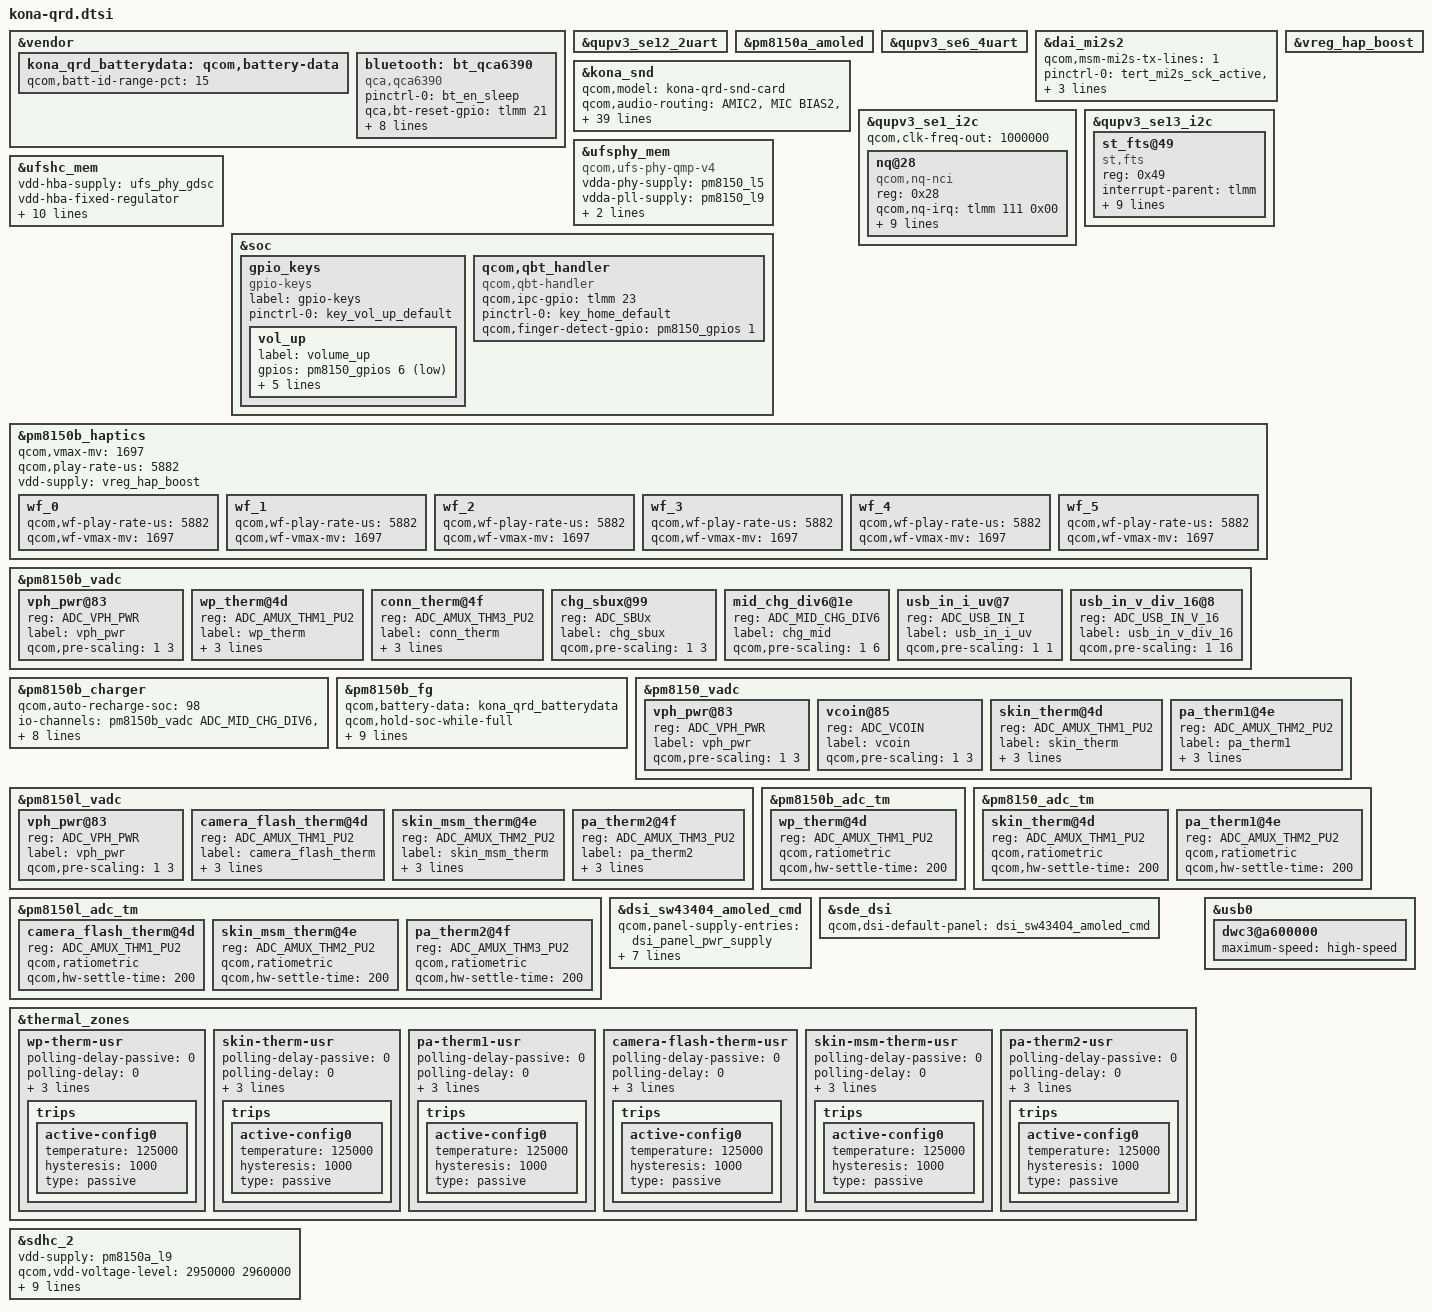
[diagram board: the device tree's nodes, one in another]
// SPDX-License-Identifier: GPL-2.0-only
/*
 * Copyright (c) 2018-2019, The Linux Foundation. All rights reserved.
 */

#include <dt-bindings/gpio/gpio.h>
#include "kona-pmic-overlay.dtsi"
#include "kona-sde-display.dtsi"
#include "kona-camera-sensor-qrd.dtsi"
#include "kona-audio-overlay.dtsi"
#include "kona-thermal-overlay.dtsi"

&vendor {
	kona_qrd_batterydata: qcom,battery-data {
		qcom,batt-id-range-pct = <15>;
		#include "fg-gen4-batterydata-mlp466274-3650mah.dtsi"
	};
};

&qupv3_se12_2uart {
	status = "okay";
};

&pm8150a_amoled {
	status = "ok";
};

&qupv3_se6_4uart {
	status = "ok";
};

&dai_mi2s2 {
	qcom,msm-mi2s-tx-lines = <1>;
	pinctrl-names = "default", "sleep";
	pinctrl-0 = <&tert_mi2s_sck_active &tert_mi2s_ws_active
			&tert_mi2s_sd0_active>;
	pinctrl-1 = <&tert_mi2s_sck_sleep &tert_mi2s_ws_sleep
			&tert_mi2s_sd0_sleep>;
};

&kona_snd {
	qcom,model = "kona-qrd-snd-card";
	qcom,audio-routing =
		"AMIC2", "MIC BIAS2",
		"MIC BIAS2", "Analog Mic2",
		"TX DMIC0", "MIC BIAS3",
		"MIC BIAS3", "Digital Mic0",
		"TX DMIC1", "MIC BIAS3",
		"MIC BIAS3", "Digital Mic1",
		"TX DMIC2", "MIC BIAS1",
		"MIC BIAS1", "Digital Mic2",
		"TX DMIC3", "MIC BIAS1",
		"MIC BIAS1", "Digital Mic3",
		"TX DMIC5", "MIC BIAS4",
		"MIC BIAS4", "Digital Mic5",
		"IN1_HPHL", "HPHL_OUT",
		"IN2_HPHR", "HPHR_OUT",
		"IN3_AUX", "AUX_OUT",
		"TX SWR_ADC0", "ADC1_OUTPUT",
		"TX SWR_ADC1", "ADC2_OUTPUT",
		"TX SWR_ADC2", "ADC3_OUTPUT",
		"TX SWR_ADC3", "ADC4_OUTPUT",
		"TX SWR_DMIC0", "DMIC1_OUTPUT",
		"TX SWR_DMIC1", "DMIC2_OUTPUT",
		"TX SWR_DMIC2", "DMIC3_OUTPUT",
		"TX SWR_DMIC3", "DMIC4_OUTPUT",
		"TX SWR_DMIC4", "DMIC5_OUTPUT",
		"TX SWR_DMIC5", "DMIC6_OUTPUT",
		"TX SWR_DMIC6", "DMIC7_OUTPUT",
		"TX SWR_DMIC7", "DMIC8_OUTPUT",
		"WSA SRC0_INP", "SRC0",
		"WSA_TX DEC0_INP", "TX DEC0 MUX",
		"WSA_TX DEC1_INP", "TX DEC1 MUX",
		"RX_TX DEC0_INP", "TX DEC0 MUX",
		"RX_TX DEC1_INP", "TX DEC1 MUX",
		"RX_TX DEC2_INP", "TX DEC2 MUX",
		"RX_TX DEC3_INP", "TX DEC3 MUX",
		"SpkrRight IN", "WSA_SPK2 OUT",
		"VA_AIF1 CAP", "VA_SWR_CLK",
		"VA_AIF2 CAP", "VA_SWR_CLK",
		"VA_AIF3 CAP", "VA_SWR_CLK",
		"VA DMIC0", "MIC BIAS3",
		"VA DMIC1", "MIC BIAS3",
		"VA DMIC2", "MIC BIAS1",
		"VA DMIC3", "MIC BIAS1",
		"VA DMIC5", "MIC BIAS4",
		"VA SWR_MIC0", "DMIC1_OUTPUT",
		"VA SWR_MIC1", "DMIC2_OUTPUT",
		"VA SWR_MIC2", "DMIC3_OUTPUT",
		"VA SWR_MIC3", "DMIC4_OUTPUT",
		"VA SWR_MIC4", "DMIC5_OUTPUT",
		"VA SWR_MIC5", "DMIC6_OUTPUT",
		"VA SWR_MIC6", "DMIC7_OUTPUT",
		"VA SWR_MIC7", "DMIC8_OUTPUT",
		"VA SWR_ADC1", "ADC2_OUTPUT";
	qcom,wsa-max-devs = <1>;
	qcom,wsa-devs = <&wsa881x_0212>, <&wsa881x_0214>;
	qcom,wsa-aux-dev-prefix = "SpkrRight", "SpkrRight";

	qcom,msm-mbhc-usbc-audio-supported = <1>;
	qcom,msm-mbhc-hphl-swh = <0>;
	qcom,msm-mbhc-gnd-swh = <0>;
};

&qupv3_se1_i2c {
	status = "ok";
	qcom,clk-freq-out = <1000000>;
	#address-cells = <1>;
	#size-cells = <0>;
	nq@28 {
		compatible = "qcom,nq-nci";
		reg = <0x28>;
		qcom,nq-irq = <&tlmm 111 0x00>;
		qcom,nq-ven = <&tlmm 6 0x00>;
		qcom,nq-firm = <&tlmm 110 0x00>;
		qcom,nq-clkreq = <&tlmm 7 0x00>;
		interrupt-parent = <&tlmm>;
		interrupts = <111 0>;
		interrupt-names = "nfc_irq";
		pinctrl-names = "nfc_active", "nfc_suspend";
		pinctrl-0 = <&nfc_int_active &nfc_enable_active
				&nfc_clk_req_active>;
		pinctrl-1 = <&nfc_int_suspend &nfc_enable_suspend
				&nfc_clk_req_suspend>;
	};
};

&qupv3_se13_i2c {
	#address-cells = <1>;
	#size-cells = <0>;

	status = "ok";

	st_fts@49 {
		compatible = "st,fts";
		reg = <0x49>;
		interrupt-parent = <&tlmm>;
		interrupts = <39 0x2008>;
		vdd-supply = <&pm8150a_l1>;
		avdd-supply = <&pm8150_l13>;
		pinctrl-names = "pmx_ts_active", "pmx_ts_suspend";
		pinctrl-0 = <&ts_active>;
		pinctrl-1 = <&ts_int_suspend &ts_reset_suspend>;
		st,irq-gpio = <&tlmm 39 0x2008>;
		st,reset-gpio = <&tlmm 38 0x00>;
		st,regulator_dvdd = "vdd";
		st,regulator_avdd = "avdd";
	};
};

&ufsphy_mem {
	compatible = "qcom,ufs-phy-qmp-v4";

	vdda-phy-supply = <&pm8150_l5>;
	vdda-pll-supply = <&pm8150_l9>;
	vdda-phy-max-microamp = <89900>;
	vdda-pll-max-microamp = <18800>;

	status = "ok";
};

&ufshc_mem {
	vdd-hba-supply = <&ufs_phy_gdsc>;
	vdd-hba-fixed-regulator;
	vcc-supply = <&pm8150_l17>;
	vcc-voltage-level = <2504000 2950000>;
	vcc-low-voltage-sup;
	vccq-supply = <&pm8150_l6>;
	vccq2-supply = <&pm8150_s4>;
	vcc-max-microamp = <800000>;
	vccq-max-microamp = <800000>;
	vccq2-max-microamp = <800000>;

	qcom,vddp-ref-clk-supply = <&pm8150_l6>;
	qcom,vddp-ref-clk-max-microamp = <100>;

	status = "ok";
};

&soc {
	gpio_keys {
		compatible = "gpio-keys";
		label = "gpio-keys";

		pinctrl-names = "default";
		pinctrl-0 = <&key_vol_up_default>;

		vol_up {
			label = "volume_up";
			gpios = <&pm8150_gpios 6 GPIO_ACTIVE_LOW>;
			linux,input-type = <1>;
			linux,code = <KEY_VOLUMEUP>;
			gpio-key,wakeup;
			debounce-interval = <15>;
			linux,can-disable;
		};
	};

	qcom,qbt_handler {
		compatible = "qcom,qbt-handler";
		qcom,ipc-gpio = <&tlmm 23 0>;
		pinctrl-names = "default";
		pinctrl-0 = <&key_home_default>;
		qcom,finger-detect-gpio = <&pm8150_gpios 1 0>;
	};
};

&vreg_hap_boost {
	status = "ok";
};

&pm8150b_haptics {
	qcom,vmax-mv = <1697>;
	qcom,play-rate-us = <5882>;
	vdd-supply = <&vreg_hap_boost>;

	wf_0 {
		/* CLICK */
		qcom,wf-play-rate-us = <5882>;
		qcom,wf-vmax-mv = <1697>;
	};

	wf_1 {
		/* DOUBLE CLICK */
		qcom,wf-play-rate-us = <5882>;
		qcom,wf-vmax-mv = <1697>;
	};

	wf_2 {
		/* TICK */
		qcom,wf-play-rate-us = <5882>;
		qcom,wf-vmax-mv = <1697>;
	};

	wf_3 {
		/* THUD */
		qcom,wf-play-rate-us = <5882>;
		qcom,wf-vmax-mv = <1697>;
	};

	wf_4 {
		/* POP */
		qcom,wf-play-rate-us = <5882>;
		qcom,wf-vmax-mv = <1697>;
	};

	wf_5 {
		/* HEAVY CLICK */
		qcom,wf-play-rate-us = <5882>;
		qcom,wf-vmax-mv = <1697>;
	};
};

&pm8150b_vadc {
	#address-cells = <1>;
	#size-cells = <0>;

	vph_pwr@83 {
		reg = <ADC_VPH_PWR>;
		label = "vph_pwr";
		qcom,pre-scaling = <1 3>;
	};

	wp_therm@4d {
		reg = <ADC_AMUX_THM1_PU2>;
		label = "wp_therm";
		qcom,ratiometric;
		qcom,hw-settle-time = <200>;
		qcom,pre-scaling = <1 1>;
	};

	conn_therm@4f {
		reg = <ADC_AMUX_THM3_PU2>;
		label = "conn_therm";
		qcom,ratiometric;
		qcom,hw-settle-time = <200>;
		qcom,pre-scaling = <1 1>;
	};

	chg_sbux@99 {
		reg = <ADC_SBUx>;
		label = "chg_sbux";
		qcom,pre-scaling = <1 3>;
	};

	mid_chg_div6@1e {
		reg = <ADC_MID_CHG_DIV6>;
		label = "chg_mid";
		qcom,pre-scaling = <1 6>;
	};

	usb_in_i_uv@7 {
		reg = <ADC_USB_IN_I>;
		label = "usb_in_i_uv";
		qcom,pre-scaling = <1 1>;
	};

	usb_in_v_div_16@8 {
		reg = <ADC_USB_IN_V_16>;
		label = "usb_in_v_div_16";
		qcom,pre-scaling = <1 16>;
	};
};

&pm8150b_charger {
	status = "ok";
	qcom,auto-recharge-soc = <98>;
	io-channels = <&pm8150b_vadc ADC_MID_CHG_DIV6>,
		      <&pm8150b_vadc ADC_USB_IN_I>,
		      <&pm8150b_vadc ADC_SBUx>,
		      <&pm8150b_vadc ADC_VPH_PWR>,
		      <&pm8150b_vadc ADC_CHG_TEMP>;
	io-channel-names = "mid_voltage",
			   "usb_in_current",
			   "sbux_res",
			   "vph_voltage",
			   "chg_temp";
	qcom,battery-data = <&kona_qrd_batterydata>;
	qcom,sw-jeita-enable;
	qcom,wd-bark-time-secs = <16>;
	qcom,suspend-input-on-debug-batt;
};

&pm8150b_fg {
	status = "ok";
	qcom,battery-data = <&kona_qrd_batterydata>;
	qcom,hold-soc-while-full;
	qcom,linearize-soc;
	qcom,five-pin-battery;
	qcom,cl-wt-enable;
	/* ESR fast calibration */
	qcom,fg-esr-timer-chg-fast = <0 7>;
	qcom,fg-esr-timer-dischg-fast = <0 7>;
	qcom,fg-esr-timer-chg-slow = <0 96>;
	qcom,fg-esr-timer-dischg-slow = <0 96>;
	qcom,fg-esr-cal-soc-thresh = <26 230>;
	qcom,fg-esr-cal-temp-thresh = <10 40>;
};

&pm8150_vadc {
	#address-cells = <1>;
	#size-cells = <0>;

	vph_pwr@83 {
		reg = <ADC_VPH_PWR>;
		label = "vph_pwr";
		qcom,pre-scaling = <1 3>;
	};

	vcoin@85 {
		reg = <ADC_VCOIN>;
		label = "vcoin";
		qcom,pre-scaling = <1 3>;
	};

	skin_therm@4d {
		reg = <ADC_AMUX_THM1_PU2>;
		label = "skin_therm";
		qcom,ratiometric;
		qcom,hw-settle-time = <200>;
		qcom,pre-scaling = <1 1>;
	};

	pa_therm1@4e {
		reg = <ADC_AMUX_THM2_PU2>;
		label = "pa_therm1";
		qcom,ratiometric;
		qcom,hw-settle-time = <200>;
		qcom,pre-scaling = <1 1>;
	};
};

&pm8150l_vadc {
	#address-cells = <1>;
	#size-cells = <0>;

	vph_pwr@83 {
		reg = <ADC_VPH_PWR>;
		label = "vph_pwr";
		qcom,pre-scaling = <1 3>;
	};

	camera_flash_therm@4d {
		reg = <ADC_AMUX_THM1_PU2>;
		label = "camera_flash_therm";
		qcom,ratiometric;
		qcom,hw-settle-time = <200>;
		qcom,pre-scaling = <1 1>;
	};

	skin_msm_therm@4e {
		reg = <ADC_AMUX_THM2_PU2>;
		label = "skin_msm_therm";
		qcom,ratiometric;
		qcom,hw-settle-time = <200>;
		qcom,pre-scaling = <1 1>;
	};

	pa_therm2@4f {
		reg = <ADC_AMUX_THM3_PU2>;
		label = "pa_therm2";
		qcom,ratiometric;
		qcom,hw-settle-time = <200>;
		qcom,pre-scaling = <1 1>;
	};
};

&pm8150b_adc_tm {
	#address-cells = <1>;
	#size-cells = <0>;

	wp_therm@4d {
		reg = <ADC_AMUX_THM1_PU2>;
		qcom,ratiometric;
		qcom,hw-settle-time = <200>;
	};
};

&pm8150_adc_tm {
	#address-cells = <1>;
	#size-cells = <0>;

	skin_therm@4d {
		reg = <ADC_AMUX_THM1_PU2>;
		qcom,ratiometric;
		qcom,hw-settle-time = <200>;
	};

	pa_therm1@4e {
		reg = <ADC_AMUX_THM2_PU2>;
		qcom,ratiometric;
		qcom,hw-settle-time = <200>;
	};
};

&pm8150l_adc_tm {
	#address-cells = <1>;
	#size-cells = <0>;

	camera_flash_therm@4d {
		reg = <ADC_AMUX_THM1_PU2>;
		qcom,ratiometric;
		qcom,hw-settle-time = <200>;
	};

	skin_msm_therm@4e {
		reg = <ADC_AMUX_THM2_PU2>;
		qcom,ratiometric;
		qcom,hw-settle-time = <200>;
	};

	pa_therm2@4f {
		reg = <ADC_AMUX_THM3_PU2>;
		qcom,ratiometric;
		qcom,hw-settle-time = <200>;
	};
};

&dsi_sw43404_amoled_cmd {
	qcom,panel-supply-entries = <&dsi_panel_pwr_supply>;
	qcom,mdss-dsi-bl-pmic-control-type = "bl_ctrl_dcs";
	qcom,mdss-dsi-bl-min-level = <1>;
	qcom,mdss-dsi-bl-max-level = <1023>;
	qcom,mdss-brightness-max-level = <255>;
	qcom,platform-te-gpio = <&tlmm 66 0>;
	qcom,platform-reset-gpio = <&tlmm 75 0>;
};

&sde_dsi {
	qcom,dsi-default-panel = <&dsi_sw43404_amoled_cmd>;
};

&thermal_zones {
	wp-therm-usr {
		polling-delay-passive = <0>;
		polling-delay = <0>;
		thermal-governor = "user_space";
		thermal-sensors = <&pm8150b_adc_tm ADC_AMUX_THM1_PU2>;
		trips {
			active-config0 {
				temperature = <125000>;
				hysteresis = <1000>;
				type = "passive";
			};
		};
	};

	skin-therm-usr {
		polling-delay-passive = <0>;
		polling-delay = <0>;
		thermal-governor = "user_space";
		thermal-sensors = <&pm8150_adc_tm ADC_AMUX_THM1_PU2>;
		trips {
			active-config0 {
				temperature = <125000>;
				hysteresis = <1000>;
				type = "passive";
			};
		};
	};

	pa-therm1-usr {
		polling-delay-passive = <0>;
		polling-delay = <0>;
		thermal-governor = "user_space";
		thermal-sensors = <&pm8150_adc_tm ADC_AMUX_THM2_PU2>;
		trips {
			active-config0 {
				temperature = <125000>;
				hysteresis = <1000>;
				type = "passive";
			};
		};
	};

	camera-flash-therm-usr {
		polling-delay-passive = <0>;
		polling-delay = <0>;
		thermal-governor = "user_space";
		thermal-sensors = <&pm8150l_adc_tm ADC_AMUX_THM1_PU2>;
		trips {
			active-config0 {
				temperature = <125000>;
				hysteresis = <1000>;
				type = "passive";
			};
		};
	};

	skin-msm-therm-usr {
		polling-delay-passive = <0>;
		polling-delay = <0>;
		thermal-governor = "user_space";
		thermal-sensors = <&pm8150l_adc_tm ADC_AMUX_THM2_PU2>;
		trips {
			active-config0 {
				temperature = <125000>;
				hysteresis = <1000>;
				type = "passive";
			};
		};
	};

	pa-therm2-usr {
		polling-delay-passive = <0>;
		polling-delay = <0>;
		thermal-governor = "user_space";
		thermal-sensors = <&pm8150l_adc_tm ADC_AMUX_THM3_PU2>;
		trips {
			active-config0 {
				temperature = <125000>;
				hysteresis = <1000>;
				type = "passive";
			};
		};
	};
};

&sdhc_2 {
	vdd-supply = <&pm8150a_l9>;
	qcom,vdd-voltage-level = <2950000 2960000>;
	qcom,vdd-current-level = <200 800000>;

	vdd-io-supply = <&pm8150a_l6>;
	qcom,vdd-io-voltage-level = <1808000 2960000>;
	qcom,vdd-io-current-level = <200 22000>;

	pinctrl-names = "active", "sleep";
	pinctrl-0 = <&sdc2_clk_on  &sdc2_cmd_on &sdc2_data_on &storage_cd>;
	pinctrl-1 = <&sdc2_clk_off &sdc2_cmd_off &sdc2_data_off &storage_cd>;

	cd-gpios = <&tlmm 77 GPIO_ACTIVE_LOW>;

	status = "ok";
};

&vendor {
	bluetooth: bt_qca6390 {
		compatible = "qca,qca6390";
		pinctrl-names = "default";
		pinctrl-0 = <&bt_en_sleep>;
		qca,bt-reset-gpio = <&tlmm 21 0>; /* BT_EN */
		qca,bt-vdd-aon-supply = <&pm8150_s6>;
		qca,bt-vdd-dig-supply = <&pm8009_s2>;
		qca,bt-vdd-rfa1-supply = <&pm8150_s5>;
		qca,bt-vdd-rfa2-supply = <&pm8150a_s8>;

		qca,bt-vdd-aon-voltage-level = <950000 950000>;
		qca,bt-vdd-dig-voltage-level = <950000 952000>;
		qca,bt-vdd-rfa1-voltage-level = <1900000 1900000>;
		qca,bt-vdd-rfa2-voltage-level = <1350000 1350000>;
	};
};

&usb0 {
	dwc3@a600000 {
		maximum-speed = "high-speed";
	};
};
